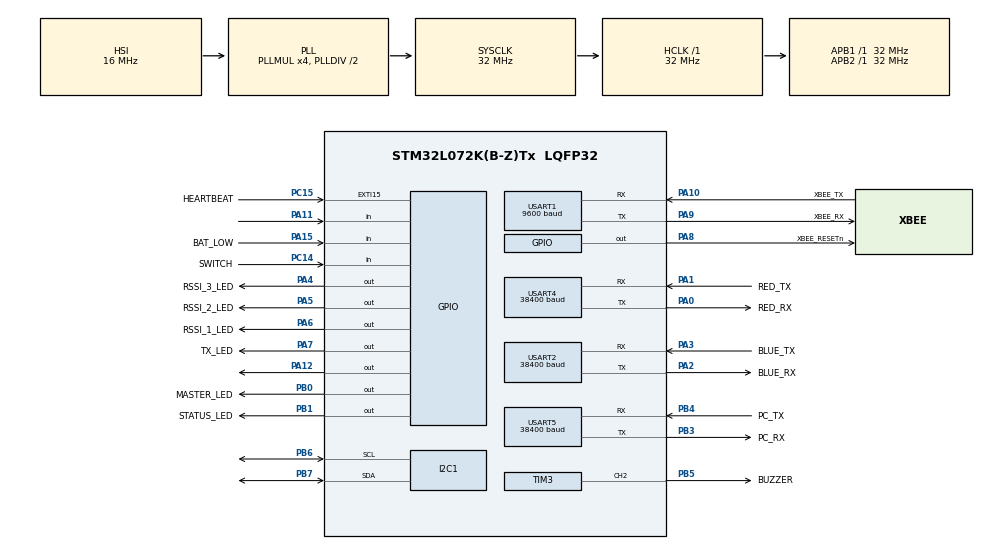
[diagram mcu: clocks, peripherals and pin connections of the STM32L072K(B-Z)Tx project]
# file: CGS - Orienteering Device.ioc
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I2C1.Timing=0x00707CBB
Mcu.Family=STM32L0
Mcu.Name=STM32L072K(B-Z)Tx
Mcu.Package=LQFP32
NVIC.EXTI4_15_IRQn=true\:0\:0\:false\:false\:true\:true\:true\:true
NVIC.TIM6_DAC_IRQn=true\:0\:0\:false\:false\:true\:true\:true\:true
NVIC.TIM7_IRQn=true\:0\:0\:false\:false\:true\:true\:true\:true
NVIC.USART1_IRQn=true\:3\:0\:true\:false\:true\:true\:true\:true
NVIC.USART2_IRQn=true\:2\:0\:true\:false\:true\:true\:true\:true
NVIC.USART4_5_IRQn=true\:1\:0\:true\:false\:true\:true\:true\:true
PA0.GPIO_Label=RED_RX
PA0.Mode=Asynchronous
PA0.Signal=USART4_TX
PA1.GPIO_Label=RED_TX
PA1.Mode=Asynchronous
PA1.Signal=USART4_RX
PA10.GPIO_Label=XBEE_TX
PA10.Mode=Asynchronous
PA10.Signal=USART1_RX
PA11.Signal=GPIO_Input
PA12.Signal=GPIO_Output
PA13.Mode=Serial_Wire
PA13.Signal=SYS_SWDIO
PA14.Mode=Serial_Wire
PA14.Signal=SYS_SWCLK
PA15.GPIO_Label=BAT_LOW
PA15.Signal=GPIO_Input
PA2.GPIO_Label=BLUE_RX
PA2.Mode=Asynchronous
PA2.Signal=USART2_TX
PA3.GPIO_Label=BLUE_TX
PA3.Mode=Asynchronous
PA3.Signal=USART2_RX
PA4.GPIO_Label=RSSI_3_LED
PA4.Signal=GPIO_Output
PA5.GPIO_Label=RSSI_2_LED
PA5.Signal=GPIO_Output
PA6.GPIO_Label=RSSI_1_LED
PA6.Signal=GPIO_Output
PA7.GPIO_Label=TX_LED
PA7.Signal=GPIO_Output
PA8.GPIO_Label=XBEE_RESETn
PA8.Signal=GPIO_Output
PA9.GPIO_Label=XBEE_RX
PA9.Mode=Asynchronous
PA9.Signal=USART1_TX
PB0.GPIO_Label=MASTER_LED
PB0.Signal=GPIO_Output
PB1.GPIO_Label=STATUS_LED
PB1.Signal=GPIO_Output
PB3.GPIO_Label=PC_RX
PB3.Mode=Asynchronous
PB3.Signal=USART5_TX
PB4.GPIO_Label=PC_TX
PB4.Mode=Asynchronous
PB4.Signal=USART5_RX
PB5.GPIO_Label=BUZZER
PB5.Signal=S_TIM3_CH2
PB6.GPIO_Pu=GPIO_PULLUP
PB6.Mode=I2C
PB6.Signal=I2C1_SCL
PB7.GPIO_Pu=GPIO_PULLUP
PB7.Mode=I2C
PB7.Signal=I2C1_SDA
PC14-OSC32_IN.GPIO_Label=SWITCH
PC14-OSC32_IN.Signal=GPIO_Input
PC15-OSC32_OUT.GPIO_Label=HEARTBEAT
PC15-OSC32_OUT.GPIO_ModeDefaultEXTI=GPIO_MODE_IT_FALLING
PC15-OSC32_OUT.Signal=GPXTI15
ProjectManager.HeapSize=0x200
ProjectManager.StackSize=0x400
ProjectManager.TargetToolchain=STM32CubeIDE
RCC.AHBFreq_Value=32000000
RCC.APB1Freq_Value=32000000
RCC.APB1TimFreq_Value=32000000
RCC.APB2Freq_Value=32000000
RCC.APB2TimFreq_Value=32000000
RCC.HCLKFreq_Value=32000000
RCC.HSI16_VALUE=16000000
RCC.HSI48_VALUE=48000000
RCC.HSI_VALUE=16000000
RCC.LSE_VALUE=32768
RCC.MSI_VALUE=2097000
RCC.PLLMUL=RCC_PLLMUL_4
RCC.SYSCLKFreq_VALUE=32000000
RCC.SYSCLKSource=RCC_SYSCLKSOURCE_PLLCLK
RCC.VCOOutputFreq_Value=64000000
SH.S_TIM3_CH2.0=TIM3_CH2,PWM Generation2 CH2
TIM3.Channel-PWM\ Generation2\ CH2=TIM_CHANNEL_2
TIM3.Period=500-1
TIM3.Prescaler=32-1
TIM3.Pulse-PWM\ Generation2\ CH2=250
TIM6.Period=320
TIM6.Prescaler=1000
TIM7.Period=3200
TIM7.Prescaler=10000
USART1.BaudRate=9600
USART1.VirtualMode-Asynchronous=VM_ASYNC
USART2.BaudRate=38400
USART2.VirtualMode-Asynchronous=VM_ASYNC
USART4.BaudRate=38400
USART4.VirtualMode-Asynchronous=VM_ASYNC
USART5.BaudRate=38400
USART5.VirtualMode-Asynchronous=VM_ASYNC
VP_TIM6_VS_ClockSourceINT.Mode=Enable_Timer
VP_TIM7_VS_ClockSourceINT.Mode=Enable_Timer
board=custom

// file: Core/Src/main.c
/* USER CODE BEGIN Header */
/**
  ******************************************************************************
  * @file           : main.c
  * @brief          : Main program body
  ******************************************************************************
  * @attention
  *
  * Copyright (c) 2024 STMicroelectronics.
  * All rights reserved.
  *
  * This software is licensed under terms that can be found in the LICENSE file
  * in the root directory of this software component.
  * If no LICENSE file comes with this software, it is provided AS-IS.
  *
  ******************************************************************************
  */
/* USER CODE END Header */
#include "main.h"
#include "i2c.h"
#include "tim.h"
#include "usart.h"
#include "gpio.h"

/* USER CODE BEGIN Includes */
#include "mainStateMachine.h"
#include "initialise.h"
/* USER CODE END Includes */

void SystemClock_Config(void);

int main(void)
{

  /* MCU Configuration--------------------------------------------------------*/

  /* Reset of all peripherals, Initializes the Flash interface and the Systick. */
  HAL_Init();

  /* Configure the system clock */
  SystemClock_Config();

  /* Initialize all configured peripherals */
  MX_GPIO_Init();
  MX_I2C1_Init();
  MX_TIM3_Init();
  MX_USART1_UART_Init();
  MX_USART2_UART_Init();
  MX_USART4_UART_Init();
  MX_USART5_UART_Init();
  MX_TIM6_Init();
  MX_TIM7_Init();
  /* USER CODE BEGIN 2 */
  initialiseHardware();
  /* USER CODE END 2 */

  /* Infinite loop */
  /* USER CODE BEGIN WHILE */
  while (1)
  {
    stateMachineLoop();
    /* USER CODE END WHILE */

  }
}

void SystemClock_Config(void)
{
  RCC_OscInitTypeDef RCC_OscInitStruct = {0};
  RCC_ClkInitTypeDef RCC_ClkInitStruct = {0};
  RCC_PeriphCLKInitTypeDef PeriphClkInit = {0};

  /** Configure the main internal regulator output voltage
  */
  __HAL_PWR_VOLTAGESCALING_CONFIG(PWR_REGULATOR_VOLTAGE_SCALE1);

  /** Initializes the RCC Oscillators according to the specified parameters
  * in the RCC_OscInitTypeDef structure.
  */
  RCC_OscInitStruct.OscillatorType = RCC_OSCILLATORTYPE_HSI;
  RCC_OscInitStruct.HSIState = RCC_HSI_ON;
  RCC_OscInitStruct.HSICalibrationValue = RCC_HSICALIBRATION_DEFAULT;
  RCC_OscInitStruct.PLL.PLLState = RCC_PLL_ON;
  RCC_OscInitStruct.PLL.PLLSource = RCC_PLLSOURCE_HSI;
  RCC_OscInitStruct.PLL.PLLMUL = RCC_PLLMUL_4;
  RCC_OscInitStruct.PLL.PLLDIV = RCC_PLLDIV_2;
  if (HAL_RCC_OscConfig(&RCC_OscInitStruct) != HAL_OK)
  {
    Error_Handler();
  }

  /** Initializes the CPU, AHB and APB buses clocks
  */
  RCC_ClkInitStruct.ClockType = RCC_CLOCKTYPE_HCLK|RCC_CLOCKTYPE_SYSCLK
                              |RCC_CLOCKTYPE_PCLK1|RCC_CLOCKTYPE_PCLK2;
  RCC_ClkInitStruct.SYSCLKSource = RCC_SYSCLKSOURCE_PLLCLK;
  RCC_ClkInitStruct.AHBCLKDivider = RCC_SYSCLK_DIV1;
  RCC_ClkInitStruct.APB1CLKDivider = RCC_HCLK_DIV1;
  RCC_ClkInitStruct.APB2CLKDivider = RCC_HCLK_DIV1;

  if (HAL_RCC_ClockConfig(&RCC_ClkInitStruct, FLASH_LATENCY_1) != HAL_OK)
  {
    Error_Handler();
  }
  PeriphClkInit.PeriphClockSelection = RCC_PERIPHCLK_USART1|RCC_PERIPHCLK_USART2
                              |RCC_PERIPHCLK_I2C1;
  PeriphClkInit.Usart1ClockSelection = RCC_USART1CLKSOURCE_PCLK2;
  PeriphClkInit.Usart2ClockSelection = RCC_USART2CLKSOURCE_PCLK1;
  PeriphClkInit.I2c1ClockSelection = RCC_I2C1CLKSOURCE_PCLK1;
  if (HAL_RCCEx_PeriphCLKConfig(&PeriphClkInit) != HAL_OK)
  {
    Error_Handler();
  }
}

void Error_Handler(void)
{
}
